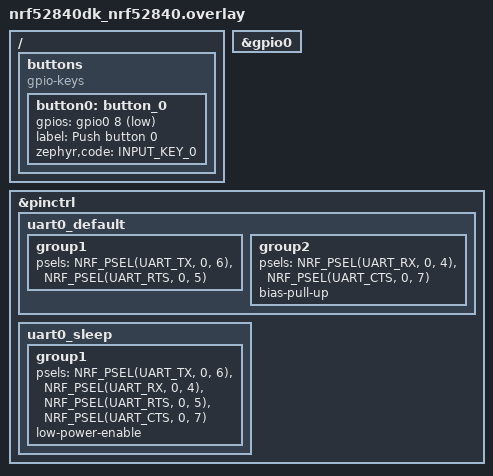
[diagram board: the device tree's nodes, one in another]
/*
 * Copyright (c) 2025 Nordic Semiconductor ASA
 *
 * SPDX-License-Identifier: LicenseRef-Nordic-5-Clause
 */

/ {
	/*
	 * Redefine sw0/button0 to use RXD1 - P0.08
	 * Thus, when sending character from host, there will be gpio interrupt,
	 * the same as originally triggered by sw0 button.
	 */
	buttons {
		compatible = "gpio-keys";

		button0: button_0 {
			gpios = <&gpio0 8 (GPIO_PULL_UP | GPIO_ACTIVE_LOW)>;
			label = "Push button 0";
			zephyr,code = <INPUT_KEY_0>;
		};
	};
};

&gpio0 {
	status = "okay";
};

/*
 * Redefine RX -> P0.04 (not used)
 */
&pinctrl {
	uart0_default: uart0_default {
		group1 {
			psels = <NRF_PSEL(UART_TX, 0, 6)>,
				<NRF_PSEL(UART_RTS, 0, 5)>;
		};

		group2 {
			psels = <NRF_PSEL(UART_RX, 0, 4)>,
				<NRF_PSEL(UART_CTS, 0, 7)>;
			bias-pull-up;
		};
	};

	uart0_sleep: uart0_sleep {
		group1 {
			psels = <NRF_PSEL(UART_TX, 0, 6)>,
				<NRF_PSEL(UART_RX, 0, 4)>,
				<NRF_PSEL(UART_RTS, 0, 5)>,
				<NRF_PSEL(UART_CTS, 0, 7)>;
			low-power-enable;
		};
	};
};
